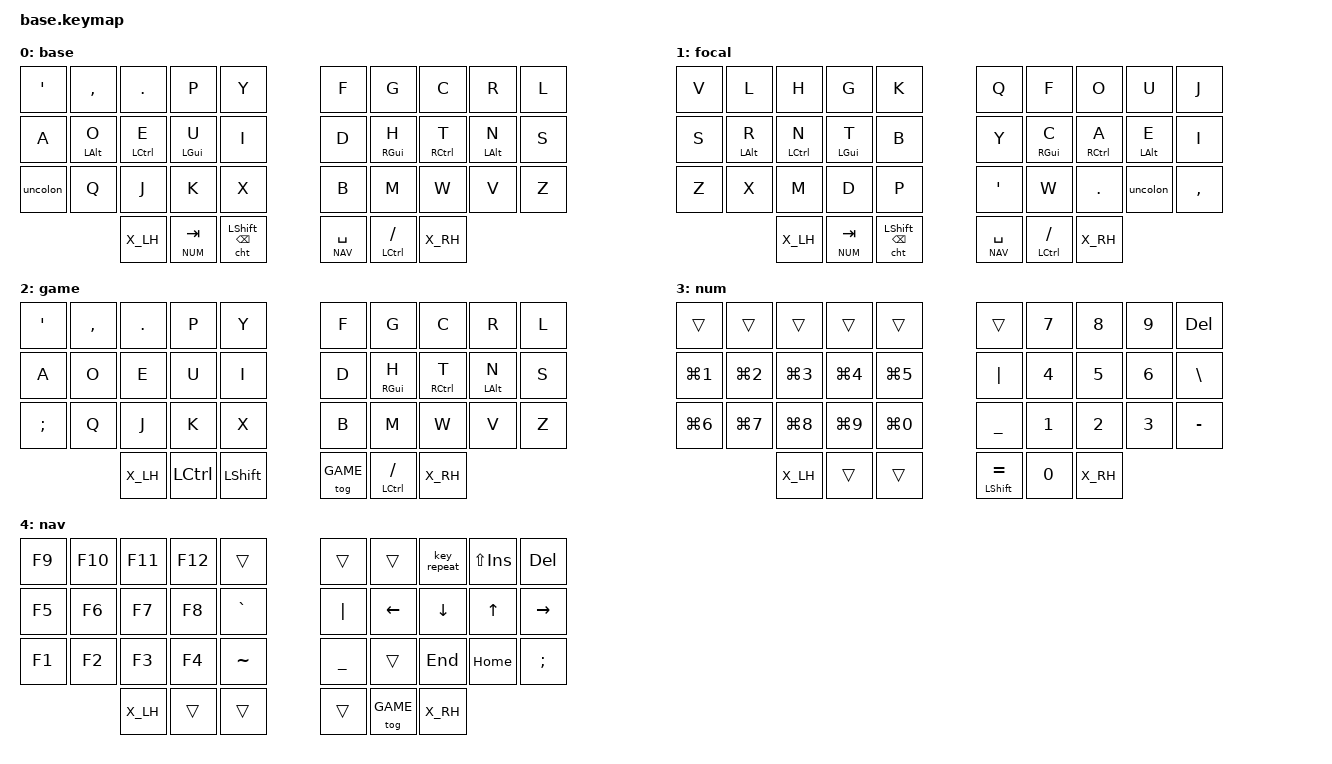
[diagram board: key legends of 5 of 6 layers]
// Copyright (c) 2022 The ZMK Contributors
// SPDX-License-Identifier: MIT

#include <behaviors.dtsi>
#include <dt-bindings/zmk/keys.h>
#include <dt-bindings/zmk/ext_power.h>

#include "../zmk-nodefree-config/helper.h"

#include "extra_keys.h"

#define ___ &trans
#define XXX &none

#define BASE 0
#define FOCAL 1
#define GAME 2
#define NUM  3
#define NAV  4
#define SYM  5

#if CONFIG_WIRELESS
    #include <dt-bindings/zmk/bt.h>
    #define _BT_SEL_KEYS_ &bt BT_SEL 0 &bt BT_SEL 1 &bt BT_SEL 2 &bt BT_SEL 3 &bt BT_CLR
#else
    #define _BT_SEL_KEYS_ &trans &trans &trans &trans &trans
#endif

#define KEYS_L LT0 LT1 LT2 LT3 LT4 LM0 LM1 LM2 LM3 LM4 LB0 LB1 LB2 LB3 LB4 LH1 LH0  // left-hand keys
#define KEYS_R RT0 RT1 RT2 RT3 RT4 RM0 RM1 RM2 RM3 RM4 RB0 RB1 RB2 RB3 RB4 RH0 RH1 // right-hand keys

/* left-hand HRMs */
ZMK_BEHAVIOR(hml, hold_tap,
    flavor = "balanced";
    tapping-term-ms = <280>;
    quick-tap-ms = <175>;                // repeat on tap-into-hold
    require-prior-idle-ms = <150>;
    bindings = <&kp>, <&kp>;
    hold-trigger-key-positions = <KEYS_R>;
    hold-trigger-on-release;             // delay positional check until key-release
)

/* right-hand HRMs */
ZMK_BEHAVIOR(hmr, hold_tap,
    flavor = "balanced";
    tapping-term-ms = <280>;
    quick-tap-ms = <175>;                // repeat on tap-into-hold
    require-prior-idle-ms = <150>;
    bindings = <&kp>, <&kp>;
    hold-trigger-key-positions = <KEYS_L>;
    hold-trigger-on-release;             // delay positional check until key-release
)

ZMK_BEHAVIOR(cht, hold_tap,
    flavor = "hold-preferred";
    tapping-term-ms = <200>;
    quick-tap-ms = <125>;
    bindings = <&kp>, <&kp>;
)

// tap: colon | shft + tap: semicolon
ZMK_BEHAVIOR(uncolon, mod_morph,
    bindings = <&kp COLON>, <&kp SEMICOLON>;
    mods = <(MOD_LSFT|MOD_RSFT)>;
)

ZMK_BEHAVIOR(vim_save, macro,
    wait-ms = <100>;
    tap-ms = <5>;
    bindings = <&kp ESC &kp COLON &kp W &kp ENTER>;
)

// use require-prior-idle-ms for combos
#undef COMBO_HOOK
#define COMBO_HOOK require-prior-idle-ms = <20>;

//ZMK_COMBO(name, bindings, keypos, layers, timeout)
ZMK_COMBO(combo_esc, &kp ESC, LB2 LB3, BASE GAME FOCAL, 100)
ZMK_COMBO(combo_vim_save, &vim_save, LB3 LB4, BASE FOCAL, 100)
ZMK_COMBO(combo_launcher, &kp LG(SPACE), RB2 RB3, BASE FOCAL, 100)
ZMK_COMBO(combo_enter, &lt SYM ENTER, RM2 RM3, BASE GAME FOCAL, 100)
ZMK_COMBO(combo_opposite_enter, &lt SYM ENTER, LM2 LM3, BASE FOCAL, 100)
ZMK_COMBO(combo_splith, &kp LG(H), RM3 RM4, BASE FOCAL, 100)
ZMK_COMBO(combo_splitv, &kp LG(V), RB3 RB4, BASE FOCAL, 100)

ZMK_COMBO(combo_terminal, &kp LG(ENTER), RM2 RM3, NUM, 100)

ZMK_LAYER(base,
     &kp SQT    &kp COMMA   &kp DOT      &kp P       &kp Y             &kp F      &kp G       &kp C       &kp R       &kp L
     &kp A      &hml LALT O &hml LCTRL E &hml LGUI U &kp I             &kp D      &hmr RGUI H &hmr RCTL T &hmr LALT N &kp S 
     &uncolon   &kp Q       &kp J        &kp K       &kp X             &kp B      &kp M       &kp W       &kp V       &kp Z
                            X_LH   &lt NUM TAB &cht LSHFT BSPC         &lt NAV SPACE  &mt LCTL FSLH  X_RH
)
ZMK_LAYER(focal,
     &kp V      &kp L       &kp H        &kp G       &kp K             &kp Q      &kp F       &kp O       &kp U       &kp J
     &kp S      &hml LALT R &hml LCTRL N &hml LGUI T &kp B             &kp Y      &hmr RGUI C &hmr RCTL A &hmr LALT E &kp I 
     &kp Z      &kp X       &kp M        &kp D       &kp P             &kp SQT    &kp W       &kp DOT     &uncolon    &kp COMMA
                            X_LH   &lt NUM TAB &cht LSHFT BSPC         &lt NAV SPACE  &mt LCTL FSLH  X_RH
)
ZMK_LAYER(game,
     &kp SQT    &kp COMMA  &kp DOT &kp P   &kp Y                      &kp F      &kp G       &kp C       &kp R       &kp L
     &kp A      &kp O      &kp E   &kp U   &kp I                      &kp D      &hmr RGUI H &hmr RCTL T &hmr LALT N &kp S
     &kp SEMI   &kp Q      &kp J   &kp K   &kp X                      &kp B      &kp M       &kp W       &kp V       &kp Z
                           X_LH   &kp LCTL &kp LSHFT                  &tog GAME  &mt LCTL FSLH  X_RH
)
ZMK_LAYER(num,
     ___        ___        ___        ___        ___                  ___        &kp N7     &kp N8     &kp N9     &kp DEL
     &kp LG(N1) &kp LG(N2) &kp LG(N3) &kp LG(N4) &kp LG(N5)           &kp PIPE   &kp N4     &kp N5     &kp N6     &kp BSLH
     &kp LG(N6) &kp LG(N7) &kp LG(N8) &kp LG(N9) &kp LG(N0)           &kp UNDER  &kp N1     &kp N2     &kp N3     &kp MINUS
                            X_LH      ___        ___                  &hmr LSHFT EQUAL  &kp N0     X_RH
)
ZMK_LAYER(nav,
     &kp F9     &kp F10    &kp F11    &kp F12    ___                  ___        ___        &key_repeat &kp LS(INS) &kp DEL
     &kp F5     &kp F6     &kp F7     &kp F8     &kp GRAVE            &kp PIPE   &kp LEFT   &kp DOWN    &kp UP      &kp RIGHT
     &kp F1     &kp F2     &kp F3     &kp F4     &kp TILDE            &kp UNDER  ___        &kp END     &kp HOME    &kp SEMI
                            X_LH      ___        ___                  ___        &tog GAME  X_RH
)
ZMK_LAYER(sym,
     &kp EXCL   &kp AT     &kp HASH   &kp DLLR   &kp PRCNT            &kp CARET  &kp AMPS   &kp STAR    &kp LPAR  &kp RPAR
     ___        ___        ___        ___        &ext_power EP_ON     &kp PIPE   ___        ___         &kp LBKT  &kp RBKT
                   _BT_SEL_KEYS_                                      &kp UNDER  ___        ___         &kp LBRC  &kp RBRC
                            X_LH      &tog FOCAL &tog GAME            &kp EQUAL  &kp PLUS   X_RH
)

